# K1921VG1T register map
Vendor: NIIET; Series: K1921VGx; File version: 2.8
CPU: other r0p1, little endian, MPU, FPU, 4 interrupt priority bits
Registers are 32-bit, read-write, reset 0x0 unless marked. A register's access mark holds for its fields unless they carry their own. Offsets are from the block's base; [hi:lo] are bit positions.

## QSPI0 — QSPI control registers
Base 0x41030000
Same registers: QSPI1 0x41040000
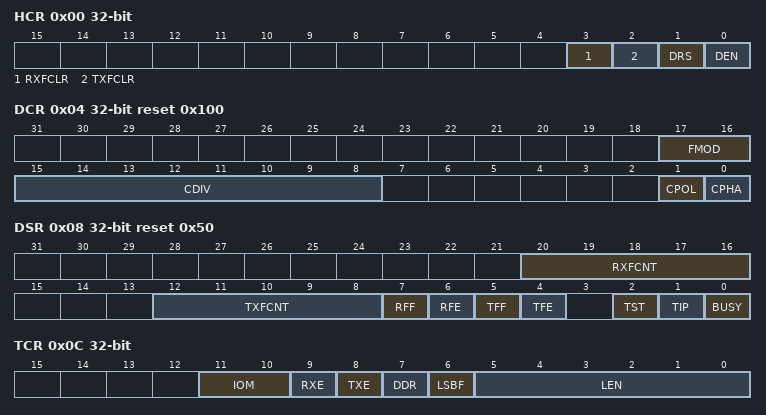
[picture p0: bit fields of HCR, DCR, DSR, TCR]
0x00 HCR — Host Control Register
  [3] RXFCLR — Rx FIFO clear
  [2] TXFCLR — Tx FIFO clear
  [1] DRS — Device reset ( SW reset )
  [0] DEN — Device enable
0x04 DCR reset 0x100 — Device Config Register
  [17:16] FMOD — Functional mode ( [00] - Std.SPI ; [01] - Reserved ; [10] - QSPI Memory Interface ; [11] - Test LoopBack )
    0=SPI (Standart SPI); 2=QSPI (QSPI Memory Interface); 3=LOOPBACK (Test LoopBack)
  [15:8] CDIV — Serial clock DIV value
  [1] CPOL — Serial clock polarity
  [0] CPHA — Serial clock phase
0x08 DSR ro reset 0x50 — Device status register
  [20:16] RXFCNT — Curent Rx FIFO Element Count
  [12:8] TXFCNT — Curent Tx FIFO Element Count
  [7] RFF — Rx FIFO Full
  [6] RFE — Rx FIFO Empty
  [5] TFF — Tx FIFO Full
  [4] TFE — Tx FIFO Empty
  [2] TST — Transfer Stall
  [1] TIP — Transfer In Progress
  [0] BUSY — Flag BUSY
0x0C TCR — Transfer Config register
  [11:10] IOM — IO Mode ( SIO/DIO/QIO ) Single/Double/Quad lines for serial IO
    0=Single lines for serial IO; 1=Double lines for serial IO; 2=Quad lines for serial IO
  [9] RXE — Serial Receiver Enable
  [8] TXE — Serial Transmitter Enable
  [7] DDR — Double Data Rate ( 0 - SDR ; 1 - DDR )
    0=SDR (Single Data Rate); 1=DDR (Double Data Rate)
  [6] LSBF — LSB First ( 0 - MSB First; 1 - LSB First )
    0=MSB (MSB First); 1=LSB (LSB First)
  [5:0] LEN — Size of data
0x10 TDR — Transfer Data register
  [31:0] VAL
0x14 TDS — Transfer Data size register
  [31:0] VAL
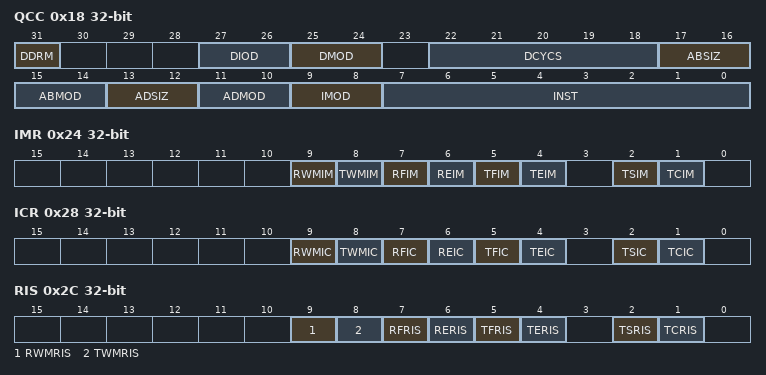
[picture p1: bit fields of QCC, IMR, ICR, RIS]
0x18 QCC — QSPI Communication Config register
  [31] DDRM ro — QSPI Double Data Rate Mode: ( 0 - SDR; 1 - DDR ) This bit sets the DDR mode for address, alt bytes, and data phases
  [27:26] DIOD — QSPI Data IO Direction
    0=WR (Indirect write mode); 1=RD (Indirect read mode)
  [25:24] DMOD — Data mode
    0=NoData; 1=Single lines for serial IO; 2=Double lines for serial IO; 3=Quad lines for serial IO
  [22:18] DCYCS — Number of dummy cycles ( This field defines of the dummy phase. ) It specifies a number of CLK cycles ( 0-31 )
  [17:16] ABSIZ — Alternate bytes size
    0=AltBytesSize_8 (8-bit alternate byte); 1=AltBytesSize_16 (16-bit alternate byte); 2=AltBytesSize_24 (24-bit alternate byte); 3=AltBytesSize_32 (32-bit alternate byte)
  [15:14] ABMOD — Alternate bytes mode
    0=AltBytesNo (No alternate bytes); 1=AltBytesSIO (Alternate bytes on a single line); 2=AltBytesDIO (Alternate bytes on two lines); 3=AltBytesQIO (Alternate bytes on four lines)
  [13:12] ADSIZ — Address size
    0=AddrSize_8 (8-bit address); 1=AddrSize_16 (16-bit address); 2=AddrSize_24 (24-bit address); 3=AddrSize_32 (32-bit address)
  [11:10] ADMOD — Address mode
    0=No (No address); 1=AddrSIO (Address on a single line); 2=AddrDIO (Address on two lines); 3=AddrQIO (Address on four lines)
  [9:8] IMOD — Instruction mode
    0=No (No instruction); 1=SIO (Instruction on a single line); 2=DIO (Instruction on two lines); 3=QIO (Instruction on four lines)
  [7:0] INST — Instruction to be sent to the external SPI defice
0x1C QAD — QSPI Address Register
  [31:0] VAL
0x20 QAB — QSPI Alternate Bytes Register
  [31:0] VAL
0x24 IMR — Interrupt Mask Register
  [9] RWMIM — Rx FIFO Watermark Interrupt Mask
  [8] TWMIM — Tx FIFO Watermark Interrupt Mask
  [7] RFIM — Rx FIFO Full Interrupt Mask
  [6] REIM — Rx FIFO Empty Interrupt Mask
  [5] TFIM — Tx FIFO Full Interrupt Mask
  [4] TEIM — Tx FIFO Empty Interrupt Mask
  [2] TSIM — Transfer Stall Interrupt Mask
  [1] TCIM — Transfer Complete Interrupt Mask
0x28 ICR — Interrupt Clear Register
  [9] RWMIC — Rx FIFO Watermark Interrupt Clear
  [8] TWMIC — Tx FIFO Watermark Interrupt Clear
  [7] RFIC — Rx FIFO Full Interrupt Clear
  [6] REIC — Rx FIFO Empty Interrupt Clear
  [5] TFIC — Tx FIFO Full Interrupt Clear
  [4] TEIC — Tx FIFO Empty Interrupt Clear
  [2] TSIC — Transfer Stall Interrupt Clear
  [1] TCIC — Transfer Complete Interrupt Clear
0x2C RIS ro — Raw Interrupt Status Register
  [9] RWMRIS — Rx FIFO Watermark raw interrupt status
  [8] TWMRIS — Tx FIFO Watermark raw interrupt status
  [7] RFRIS — Rx FIFO Full raw interrupt status
  [6] RERIS — Rx FIFO Empty raw interrupt status
  [5] TFRIS — Tx FIFO Full raw interrupt status
  [4] TERIS — Tx FIFO Empty raw interrupt status
  [2] TSRIS — Transfer Stall raw interrupt status
  [1] TCRIS — Transfer Complete raw interrupt status
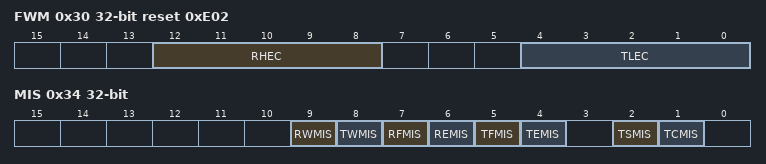
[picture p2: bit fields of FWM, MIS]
0x30 FWM reset 0xE02 — Fifo's WaterMarks Register
  [12:8] RHEC — Rx FIFO High Element Count limit ( High Watermark )
  [4:0] TLEC — Tx FIFO Low Element Count limit ( Low Watermark )
0x34 MIS ro — Masked Interrupt Status Register
  [9] RWMIS — Rx FIFO Watermark masked interrupt status
  [8] TWMIS — Tx FIFO Watermark masked interrupt status
  [7] RFMIS — Rx FIFO Full masked interrupt status
  [6] REMIS — Rx FIFO Empty masked interrupt status
  [5] TFMIS — Tx FIFO Full masked interrupt status
  [4] TEMIS — Tx FIFO Empty masked interrupt status
  [2] TSMIS — Transfer Stall masked interrupt status
  [1] TCMIS — Transfer Complete masked interrupt status
